# slm32x030 register map
Vendor: Keil; File version: 1.0.1
CPU: CM0 r2p1, little endian, no MPU, no FPU, 4 interrupt priority bits
Registers are 32-bit, read-write, reset 0x0 unless marked. A register's access mark holds for its fields unless they carry their own. Offsets are from the block's base; [hi:lo] are bit positions; {n}, {i} and the like mark numbered series; 'fields as' and 'values as' point back to an identical list.

## RTC — Real time clock RTC
Base 0x40002800
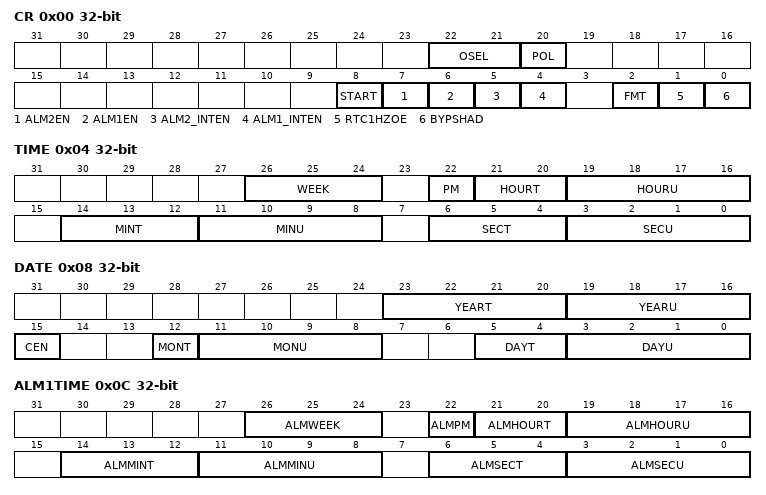
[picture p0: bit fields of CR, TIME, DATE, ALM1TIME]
0x00 CR access not given — RTC_CR
  [22:21] OSEL — Later Add Description
  [20] POL — Later Add Description
  [8] START — Later Add Description
  [7] ALM2EN — Later Add Description
  [6] ALM1EN — Later Add Description
  [5] ALM2_INTEN — Later Add Description
  [4] ALM1_INTEN — Later Add Description
  [2] FMT — Later Add Description
  [1] RTC1HZOE — Later Add Description
  [0] BYPSHAD — Later Add Description
0x04 TIME access not given — RTC_TIME
  [26:24] WEEK — Later Add Description
  [22] PM — Later Add Description
  [21:20] HOURT — Later Add Description
  [19:16] HOURU — Later Add Description
  [14:12] MINT — Later Add Description
  [11:8] MINU — Later Add Description
  [6:4] SECT — Later Add Description
  [3:0] SECU — Later Add Description
0x08 DATE access not given — RTC_DATE
  [23:20] YEART — Later Add Description
  [19:16] YEARU — Later Add Description
  [15] CEN — Later Add Description
  [12] MONT — Later Add Description
  [11:8] MONU — Later Add Description
  [5:4] DAYT — Later Add Description
  [3:0] DAYU — Later Add Description
0x0C ALM1TIME access not given — RTC_ALM1TIME
  [26:24] ALMWEEK — Later Add Description
  [22] ALMPM — Later Add Description
  [21:20] ALMHOURT — Later Add Description
  [19:16] ALMHOURU — Later Add Description
  [14:12] ALMMINT — Later Add Description
  [11:8] ALMMINU — Later Add Description
  [6:4] ALMSECT — Later Add Description
  [3:0] ALMSECU — Later Add Description
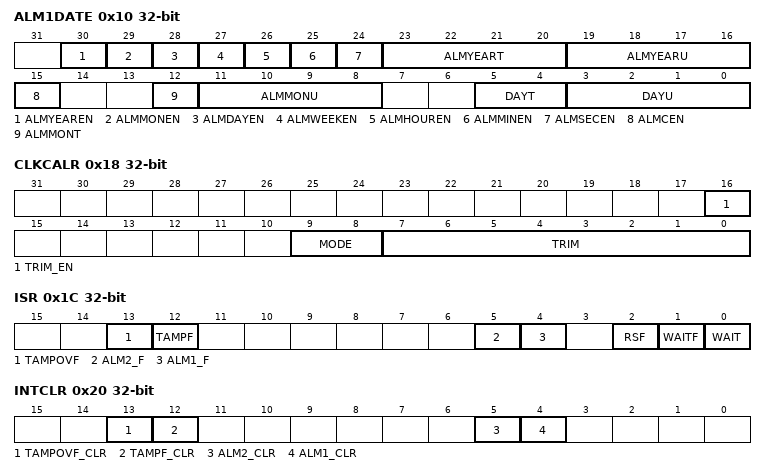
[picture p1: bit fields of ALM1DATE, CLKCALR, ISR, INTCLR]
0x10 ALM1DATE access not given — RTC_ALM1DATE
  [30] ALMYEAREN — Later Add Description
  [29] ALMMONEN — Later Add Description
  [28] ALMDAYEN — Later Add Description
  [27] ALMWEEKEN — Later Add Description
  [26] ALMHOUREN — Later Add Description
  [25] ALMMINEN — Later Add Description
  [24] ALMSECEN — Later Add Description
  [23:20] ALMYEART — Later Add Description
  [19:16] ALMYEARU — Later Add Description
  [15] ALMCEN — Later Add Description
  [12] ALMMONT — Later Add Description
  [11:8] ALMMONU — Later Add Description
  [5:4] DAYT — Later Add Description
  [3:0] DAYU — Later Add Description
0x14 ALM2PRD access not given — RTC_ALM2PRD
  [3:0] ALM2PR_CNT — Later Add Description
0x18 CLKCALR access not given — RTC_CLKCALR
  [16] TRIM_EN — Later Add Description
  [9:8] MODE — Later Add Description
  [7:0] TRIM — Later Add Description
0x1C ISR access not given — RTC_ISR
  [13] TAMPOVF — Later Add Description
  [12] TAMPF — Later Add Description
  [5] ALM2_F — Later Add Description
  [4] ALM1_F — Later Add Description
  [2] RSF — Later Add Description
  [1] WAITF — Later Add Description
  [0] WAIT — Later Add Description
0x20 INTCLR access not given — RTC_INTCLR
  [13] TAMPOVF_CLR — Later Add Description
  [12] TAMPF_CLR — Later Add Description
  [5] ALM2_CLR — Later Add Description
  [4] ALM1_CLR — Later Add Description
0x24 WPR access not given — RTC_WPR
  [7:0] WPR — Later Add Description
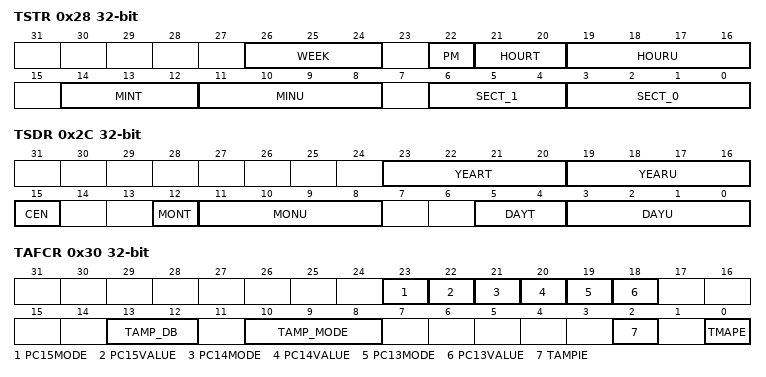
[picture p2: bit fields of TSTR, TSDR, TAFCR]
0x28 TSTR access not given — RTC_TSTR
  [26:24] WEEK — Later Add Description
  [22] PM — Later Add Description
  [21:20] HOURT — Later Add Description
  [19:16] HOURU — Later Add Description
  [14:12] MINT — Later Add Description
  [11:8] MINU — Later Add Description
  [6:4] SECT_1 — Later Add Description
  [3:0] SECT_0 — Later Add Description
0x2C TSDR access not given — RTC_TSDR
  fields as DATE
0x30 TAFCR access not given — RTC_TAFCR
  [23] PC15MODE — Later Add Description
  [22] PC15VALUE — Later Add Description
  [21] PC14MODE — Later Add Description
  [20] PC14VALUE — Later Add Description
  [19] PC13MODE — Later Add Description
  [18] PC13VALUE — Later Add Description
  [13:12] TAMP_DB — Later Add Description
  [10:8] TAMP_MODE — Later Add Description
  [2] TAMPIE — Later Add Description
  [0] TMAPE — Later Add Description
{0x50+4i} BKP{i}R access not given (i=0..4) — RTC_BKP{i}R
  [31:0] BKP — Later Add Description
